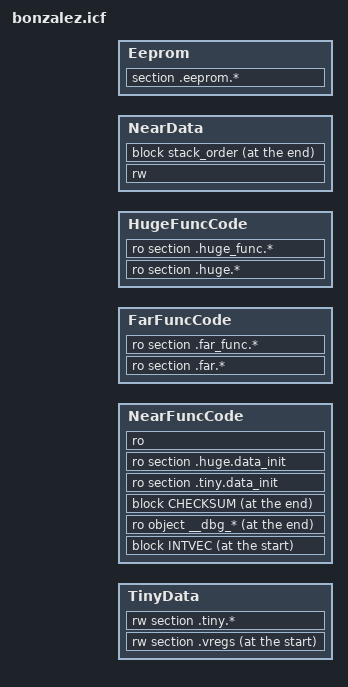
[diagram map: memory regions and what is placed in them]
/////////////////////////////////////////////////////////////////
//      Example ILINK command file for
//      STM8 IAR C/C++ Compiler and Assembler.
//
//      Copyright 2010 IAR Systems AB.
//
//      $Revision: 1623 $
//
/////////////////////////////////////////////////////////////////

define memory with size = 8M;

define symbol __ICFEDIT_region_ROM_start__ = 0x08000;
define symbol __ICFEDIT_region_ROM_end__   = 0x0FFFF;
define symbol __ICFEDIT_region_RAM_start__ = 0x100;
define symbol __ICFEDIT_region_RAM_end__   = 0x7FF;

define symbol __ICFEDIT_region_RUN_TIME_RAM_CHCK_start__  = 0x00;
define symbol __ICFEDIT_region_RUN_TIME_RAM_CHCK_end__ = 0x0f;
//define symbol __ICFEDIT_region_CLASSB_start__ = 0x010;
//define symbol __ICFEDIT_region_CLASSB_end__   = 0x07F;

define symbol __ICFEDIT_size_stack_bottom__ = 0x4;

export symbol  __ICFEDIT_region_ROM_start__;
export symbol __ICFEDIT_region_ROM_end__;
export symbol __ICFEDIT_region_RAM_start__;
export symbol  __ICFEDIT_region_RAM_end__;
//export symbol  __ICFEDIT_region_CLASSB_start__;
//export symbol  __ICFEDIT_region_CLASSB_end__;

/////////////////////////////////////////////////////////////////

define region TinyData = [from 0x00 to 0xFF];

define region NearFuncCode = [from __ICFEDIT_region_ROM_start__ to __ICFEDIT_region_ROM_end__];

define region FarFuncCode = [from 0x8000 to 0xFFFF];

define region HugeFuncCode = [from 0x8000 to 0xFFFF];

define region NearData = [from __ICFEDIT_region_RAM_start__ to __ICFEDIT_region_RAM_end__];

define region Eeprom = [from 0x4000 to 0x407F];

define region BootROM = [from 0x6000 to 0x67FF];

// define region RUN_TIME_RAM_CHCK_region = [from __ICFEDIT_region_RUN_TIME_RAM_CHCK_start__ to __ICFEDIT_region_RUN_TIME_RAM_CHCK_end__];

// define region CLASS_B_RAM_region = [from __ICFEDIT_region_CLASSB_start__ to __ICFEDIT_region_CLASSB_end__];

// Block definition /////////////////////////

define block CSTACK with size = 0x00  {};

define block HEAP  with size = 0x00 {};

define block INTVEC with size = 0x80 { ro section .intvec };

define block STACK_BOTTOM_B  with size = __ICFEDIT_size_stack_bottom__  { section STACK_BOTTOM };
define block stack_order with fixed order { block STACK_BOTTOM_B, block CSTACK, block HEAP };

define block CHECKSUM  { section .checksum };
// with alignment = 2

// Initialization //////////////////////////

initialize by copy { rw };
initialize by copy { ro section .tiny.rodata };
do not initialize { section .vregs };
do not initialize { section .*.noinit };
do not initialize  { rw section STACK_BOTTOM,
                     rw section RUN_TIME_RAM_CHCK,
                     rw section CLASS_B_RAM,
                     rw section CLASS_B_RAM_REV };

// Placement //////////////////////////////

// place in CLASS_B_RAM_region     { readwrite data section CLASS_B_RAM, readwrite data section CLASS_B_RAM_REV  };

// place in RUN_TIME_RAM_CHCK_region { readwrite data section RUN_TIME_RAM_CHCK  };

place at start of TinyData      { rw section .vregs };
place in TinyData               { rw section .tiny.* };

place in NearData               { rw };     // includes rw section .near.*
place at end of NearData        { block stack_order };

place at start of NearFuncCode  { block INTVEC };
place at end of NearFuncCode    { ro object __dbg_*, block CHECKSUM };
place in NearFuncCode           { ro section .tiny.data_init,
                                  ro section .huge.data_init,
                                  ro };     // includes ro section .near_func.*

place in FarFuncCode            { ro section .far.*,
                                  ro section .far_func.* };

place in HugeFuncCode           { ro section .huge.*,
                                  ro section .huge_func.* };

place in Eeprom                 { section .eeprom.* };

/////////////////////////////////////////////////////////////////
